# MSS_CTRL_MSS_CTRL_50D00000h register map
Vendor: Texas Instruments
Registers are 32-bit, read-write, reset values left out (the file's numbers can be read two ways) unless marked. A register's access mark holds for its fields unless they carry their own. Offsets are as the file gives them; [hi:lo] are bit positions; {n}, {i} and the like mark numbered series.

## MSS_CTRL (part 2 of 4)
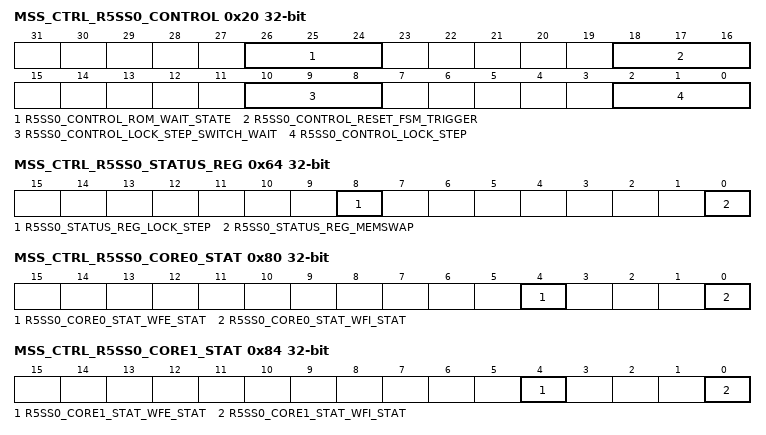
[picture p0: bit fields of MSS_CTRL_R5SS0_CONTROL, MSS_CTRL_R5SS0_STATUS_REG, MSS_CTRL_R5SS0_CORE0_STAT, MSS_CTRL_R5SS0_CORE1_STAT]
0x20 MSS_CTRL_R5SS0_CONTROL — This register is used to configure R5SS0 in Lock step or Dual core mode. The mode change can be affected only once in a SOC power cycle.
  [26:24] R5SS0_CONTROL_ROM_WAIT_STATE — Writing '111' enables a single cycle wait state with respect to CR5A_clk for rom access.This needs to be set when R5 clock is at 400MHZ and Interconnect-clk is at 200MHZ. [because it is a timing issue in this scenario]
  [18:16] R5SS0_CONTROL_RESET_FSM_TRIGGER — Write pulse bit field:Writing 3'b111 will trigger the reset FSM. Reset FSM ensures reset to R5SS and inturn ensures the latching of lock_step and also mem_swap bit
  [10:8] R5SS0_CONTROL_LOCK_STEP_SWITCH_WAIT — Writing 3'b111 ensures switch happens only after R5SS reset. Orelse it will be a immediate switch.
  [2:0] R5SS0_CONTROL_LOCK_STEP — Writing 3'b000 ensures R5 to be in Dual-Core mode. Note: The change happens after the R5SS reset assertion if corresponding R5SS_CONTROL_LOCK_STEP_SWITCH_WAIT is set. Or else the switiching to Dual-core happens on the fly.
0x28 MSS_CTRL_R5SS0_FORCE_WFI — This register is used to override and force WFI from R5SS0 to RCM.
  [2:0] R5SS0_FORCE_WFI_CR5_WFI_OVERIDE — Writing 3'b111 will force the wfi signals of R5SS to 1
0x40 MSS_CTRL_R5SS0_CORE0_HALT — This register is used to Halt or Unhalt R5SS0 Core 0
  [2:0] R5SS0_CORE0_HALT_HALT — Writing '000' will unhalt CR5A. This register should be written only once.
0x44 MSS_CTRL_R5SS0_CORE1_HALT — This register is used to Halt or Unhalt R5SS0 Core 1
  [2:0] R5SS0_CORE1_HALT_HALT — Writing '000' will unhalt for CR5B. This register should be written only once.
0x64 MSS_CTRL_R5SS0_STATUS_REG ro — This register shows whether R5SS0 is in Lock step or Dual core mode.
  [8] R5SS0_STATUS_REG_LOCK_STEP — Reading1:confirms R5SS is in lockstep mode. Reading0:confirms R5SS is in Dual-core mode.
  [0] R5SS0_STATUS_REG_MEMSWAP — Reading1:confirms ROM is Eclipsed from with RAM for R5.
0x80 MSS_CTRL_R5SS0_CORE0_STAT ro — This register shows the WFI WFE status of R5SS0 Core 0
  [4] R5SS0_CORE0_STAT_WFE_STAT — WFE Status
  [0] R5SS0_CORE0_STAT_WFI_STAT — WFI Status
0x84 MSS_CTRL_R5SS0_CORE1_STAT ro — This register shows the WFI WFE status of R5SS0 Core 1
  [4] R5SS0_CORE1_STAT_WFE_STAT — WFE Status
  [0] R5SS0_CORE1_STAT_WFI_STAT — WFI Status
0x150 MSS_CTRL_R5SS0_TEINIT — This register is used to set the Exception state of R5SS[x] at reset.
  [0] R5SS0_TEINIT_TEINIT — Exception handling state at reset. 0-ARM 1-Thumb
0x300 MSS_CTRL_R5SS0_ATCM_MEM_INIT — This register is used to initialise the data and ECC of ATCM memory of R5SS0 .
  [0] R5SS0_ATCM_MEM_INIT_MEM_INIT — Write_pulse bit field:Writing 1'b1 will start initializing the ATCM banks of CR5A/B. Value in each row is initialized to 0x0C_0000_0000
0x304 MSS_CTRL_R5SS0_ATCM_MEM_INIT_DONE access not given — This register is used to indicate the ATCM memory initialization completion for R5SS0.
  [0] R5SS0_ATCM_MEM_INIT_DONE_MEM_INIT_DONE — This field will be high once initialization of ATCM banks is finished. Writing 1'b1 would clear the bit. (access R/W1TC)
0x308 MSS_CTRL_R5SS0_ATCM_MEM_INIT_STATUS ro — This register is used to indicate the status of ongoing memory initialization for ATCM memory of R5SS0.
  [0] R5SS0_ATCM_MEM_INIT_STATUS_MEM_STATUS — 1'b0: No initialization is happening for ATCM banks of CR5A/B1'b1: Initialization is in progress for ATCM banks of CR5A/B
0x30C MSS_CTRL_R5SS0_BTCM_MEM_INIT — This register is used to initialise the data and ECC of BTCM memory of R5SS0 .
  [0] R5SS0_BTCM_MEM_INIT_MEM_INIT — Write_pulse bit field:Writing 1'b1 will start initializing the B0/1TCM banks of CR5A/B
0x310 MSS_CTRL_R5SS0_BTCM_MEM_INIT_DONE access not given — This register is used to indicate the BTCM memory initialization completion for R5SS0.
  [0] R5SS0_BTCM_MEM_INIT_DONE_MEM_INIT_DONE — This field will be high once initialization of B0/1TCM banks is finished. Writing 1'b1 would clear the bit. (access R/W1TC)
0x314 MSS_CTRL_R5SS0_BTCM_MEM_INIT_STATUS ro — This register is used to indicate the status of ongoing memory initialization for BTCM memory of R5SS0.
  [0] R5SS0_BTCM_MEM_INIT_STATUS_MEM_STATUS — 1'b0: No initialization is happening for B0/1TCM banks of CR5A/B1'b1: Initialization is in progress for B0/1TCM banks of CR5A/B
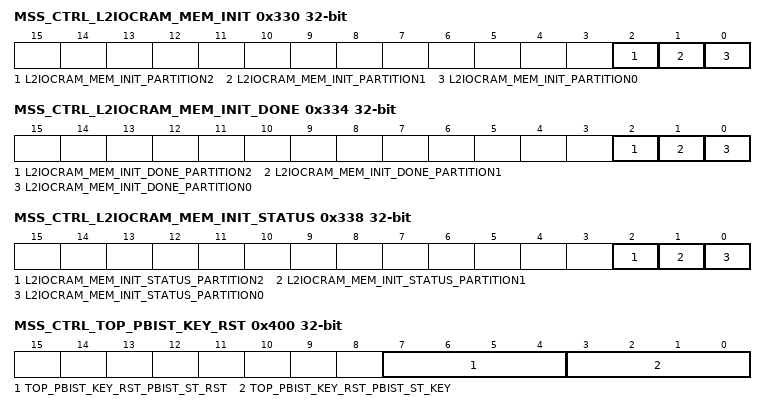
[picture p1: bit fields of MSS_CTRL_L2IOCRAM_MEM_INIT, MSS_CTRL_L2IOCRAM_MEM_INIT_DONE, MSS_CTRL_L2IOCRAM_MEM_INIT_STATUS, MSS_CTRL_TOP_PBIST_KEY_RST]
0x330 MSS_CTRL_L2IOCRAM_MEM_INIT — This register is used to initialise the data and ECC of L2OCRAM.
  [2] L2IOCRAM_MEM_INIT_PARTITION2 — Write_pulse bit field:Writing 1'b1 will start initializing the L2 Bank2. Value in each row is initialized to 0x0
  [1] L2IOCRAM_MEM_INIT_PARTITION1 — Write_pulse bit field:Writing 1'b1 will start initializing the L2 Bank1. Value in each row is initialized to 0x0
  [0] L2IOCRAM_MEM_INIT_PARTITION0 — Write_pulse bit field:Writing 1'b1 will start initializing the L2 Bank0. Value in each row is initialized to 0x0
0x334 MSS_CTRL_L2IOCRAM_MEM_INIT_DONE access not given — This register is used to indicate the L2OCRAM memory initialization completion .
  [2] L2IOCRAM_MEM_INIT_DONE_PARTITION2 — This field will be high once intialization of L2 bank2 is finished. Writing 1'b1 would clear the bit (access R/W1TC)
  [1] L2IOCRAM_MEM_INIT_DONE_PARTITION1 — This field will be high once intialization of L2 bank1 is finished. Writing 1'b1 would clear the bit (access R/W1TC)
  [0] L2IOCRAM_MEM_INIT_DONE_PARTITION0 — This field will be high once intialization of L2 bank0 is finished. Writing 1'b1 would clear the bit (access R/W1TC)
0x338 MSS_CTRL_L2IOCRAM_MEM_INIT_STATUS ro — This register is used to indicate the status of ongoing memory initialization for L2OCRAM.
  [2] L2IOCRAM_MEM_INIT_STATUS_PARTITION2 — 1'b0: No initialization is happening for L2 bank2 1'b1: Initialization is in progress for L2 bank2
  [1] L2IOCRAM_MEM_INIT_STATUS_PARTITION1 — 1'b0: No initialization is happening for L2 bank11'b1: Initialization is in progress for L2 bank1
  [0] L2IOCRAM_MEM_INIT_STATUS_PARTITION0 — 1'b0: No initialization is happening for L2 bank0 1'b1: Initialization is in progress for L2 bank0
0x33C MSS_CTRL_MAILBOXRAM_MEM_INIT — This register is used to initialise the data and ECC of MBOX_SRAM.
  [0] MAILBOXRAM_MEM_INIT_MEM0_INIT — Write_pulse bit field:Writing 1'b1 will start initializing the MSS_MBOX. Value in each row is initialized to 0x0
0x340 MSS_CTRL_MAILBOXRAM_MEM_INIT_DONE access not given — This register is used to indicate the MBOX_SRAM memory initialization completion .
  [0] MAILBOXRAM_MEM_INIT_DONE_MEM0_DONE — This field will be high once intialization of MSS_MBOX is finished. Writing 1'b1 would clear the bit (access R/W1TC)
0x344 MSS_CTRL_MAILBOXRAM_MEM_INIT_STATUS ro — This register is used to indicate the status of ongoing memory initialization for MBOX_SRAM.
  [0] MAILBOXRAM_MEM_INIT_STATUS_MEM0_STATUS — 1'b0: No initialization is happening for MSS_MBOX 1'b1: Initialization is in progress for MSS_MBOX
0x348 MSS_CTRL_TPCC_MEM_INIT — This register is used to initialise the data and ECC of EDMA_TPCC RAM.
  [0] TPCC_MEM_INIT_TPCC_A_MEMINIT_START — Write_pulse bit field:Writing 1'b1 will start initializing the MSS_TPCCA
0x34C MSS_CTRL_TPCC_MEM_INIT_DONE access not given — This register is used to indicate the EDMA_TPCC memory initialization completion .
  [0] TPCC_MEM_INIT_DONE_TPCC_A_MEMINIT_DONE — This field will be high once intialization of MSS_TPCCA is finished. Writing 1'b1 would clear the bit (access R/W1TC)
0x350 MSS_CTRL_TPCC_MEMINIT_STATUS ro — This register is used to indicate the status of ongoing memory initialization for EDMA_TPCC RAM.
  [0] TPCC_MEMINIT_STATUS_TPCC_A_MEMINIT_STATUS — 1'b0: No initialization is happening for MSS_TPCCA1'b1: Initialization is in progress for MSS_TPCCB
0x400 MSS_CTRL_TOP_PBIST_KEY_RST — This register is used to enable Top Pbist module.
  [7:4] TOP_PBIST_KEY_RST_PBIST_ST_RST — MSS PBIST controller will be brought out of reset when value is 0xA
  [3:0] TOP_PBIST_KEY_RST_PBIST_ST_KEY — Top PBIST Selftest Key. Valid value is 0x5
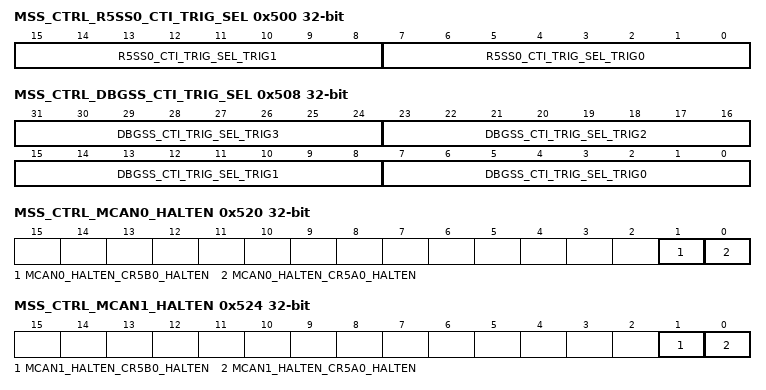
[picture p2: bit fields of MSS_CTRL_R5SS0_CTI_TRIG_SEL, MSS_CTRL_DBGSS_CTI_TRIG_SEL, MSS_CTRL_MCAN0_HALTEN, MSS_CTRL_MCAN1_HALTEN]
0x500 MSS_CTRL_R5SS0_CTI_TRIG_SEL — This register is used to select the two CTI trigger sources for R5SS[x]
  [15:8] R5SS0_CTI_TRIG_SEL_TRIG1 — Used for selecting the trigger source for 1st trigger of MSS_R5SS
  [7:0] R5SS0_CTI_TRIG_SEL_TRIG0 — Used for selecting the trigger source for 0th trigger of MSS_R5SS
0x508 MSS_CTRL_DBGSS_CTI_TRIG_SEL — This register is used to select thefour CTI trigger sources for DEBUGSS.
  [31:24] DBGSS_CTI_TRIG_SEL_TRIG3 — Used for selecting the trigger source for 3rd trigger of ONE_MCU_CTI
  [23:16] DBGSS_CTI_TRIG_SEL_TRIG2 — Used for selecting the trigger source for 2nd trigger of ONE_MCU_CTI
  [15:8] DBGSS_CTI_TRIG_SEL_TRIG1 — Used for selecting the trigger source for 1st trigger of ONE_MCU_CTI
  [7:0] DBGSS_CTI_TRIG_SEL_TRIG0 — Used for selecting the trigger source for 0th trigger of ONE_MCU_CTI
0x520 MSS_CTRL_MCAN0_HALTEN — This register selects which R5 CPU when debug halted shall halt MCAN[x] Peripheral.
  [1] MCAN0_HALTEN_CR5B0_HALTEN — 1'b0: IP Halt disabled with corresponding CPU halt1'b1: IP Halt enabled with corresponding CPU halt
  [0] MCAN0_HALTEN_CR5A0_HALTEN — 1'b0: IP Halt disabled with corresponding CPU halt1'b1: IP Halt enabled with corresponding CPU halt
0x524 MSS_CTRL_MCAN1_HALTEN — This register selects which R5 CPU when debug halted shall halt MCAN[x] Peripheral.
  [1] MCAN1_HALTEN_CR5B0_HALTEN — 1'b0: IP Halt disabled with corresponding CPU halt1'b1: IP Halt enabled with corresponding CPU halt
  [0] MCAN1_HALTEN_CR5A0_HALTEN — 1'b0: IP Halt disabled with corresponding CPU halt1'b1: IP Halt enabled with corresponding CPU halt
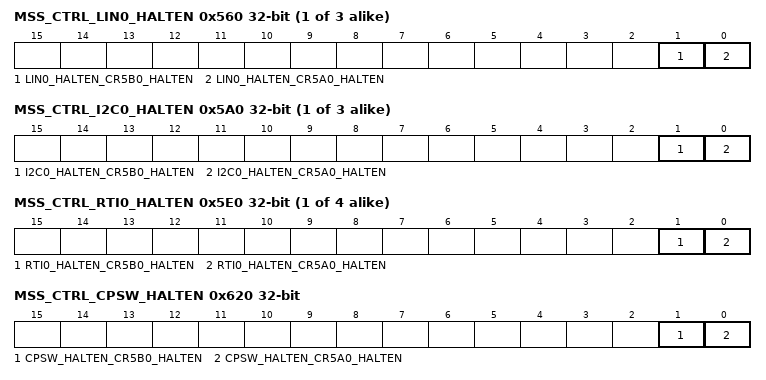
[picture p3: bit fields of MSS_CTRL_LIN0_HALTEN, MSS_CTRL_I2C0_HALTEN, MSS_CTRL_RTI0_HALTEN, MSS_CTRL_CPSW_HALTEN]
{0x560+4i} MSS_CTRL_LIN{i}_HALTEN (i=0..2) — This register selects which R5 CPU when debug halted shall halt LIN[x] Peripheral.
  [1] LIN{i}_HALTEN_CR5B0_HALTEN — 1'b0: IP Halt disabled with corresponding CPU halt1'b1: IP Halt enabled with corresponding CPU halt
  [0] LIN{i}_HALTEN_CR5A0_HALTEN — 1'b0: IP Halt disabled with corresponding CPU halt1'b1: IP Halt enabled with corresponding CPU halt
{0x5A0+4i} MSS_CTRL_I2C{i}_HALTEN (i=0..2) — This register selects which R5 CPU when debug halted shall halt I2C[x] Peripheral.
  [1] I2C{i}_HALTEN_CR5B0_HALTEN — 1'b0: IP Halt disabled with corresponding CPU halt1'b1: IP Halt enabled with corresponding CPU halt
  [0] I2C{i}_HALTEN_CR5A0_HALTEN — 1'b0: IP Halt disabled with corresponding CPU halt1'b1: IP Halt enabled with corresponding CPU halt
{0x5E0+4i} MSS_CTRL_RTI{i}_HALTEN (i=0..3) — This register selects which R5 CPU when debug halted shall halt RTI[x] Peripheral.
  [1] RTI{i}_HALTEN_CR5B0_HALTEN — 1'b0: IP Halt disabled with corresponding CPU halt1'b1: IP Halt enabled with corresponding CPU halt
  [0] RTI{i}_HALTEN_CR5A0_HALTEN — 1'b0: IP Halt disabled with corresponding CPU halt1'b1: IP Halt enabled with corresponding CPU halt
0x620 MSS_CTRL_CPSW_HALTEN — This register selects which R5 CPU when debug halted shall halt CPSW Peripheral.
  [1] CPSW_HALTEN_CR5B0_HALTEN — 1'b0: IP Halt disabled with corresponding CPU halt1'b1: IP Halt enabled with corresponding CPU halt
  [0] CPSW_HALTEN_CR5A0_HALTEN — 1'b0: IP Halt disabled with corresponding CPU halt1'b1: IP Halt enabled with corresponding CPU halt
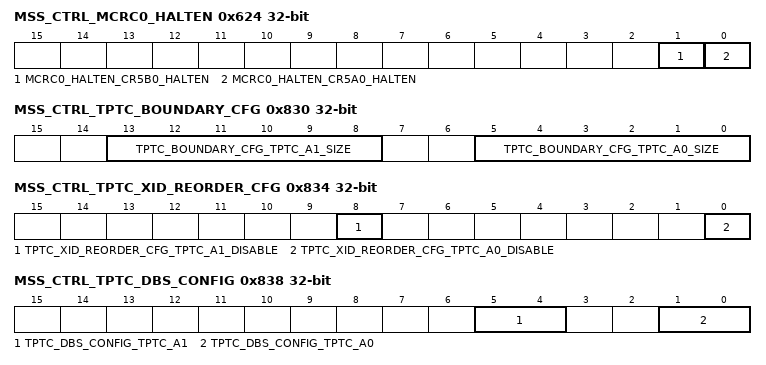
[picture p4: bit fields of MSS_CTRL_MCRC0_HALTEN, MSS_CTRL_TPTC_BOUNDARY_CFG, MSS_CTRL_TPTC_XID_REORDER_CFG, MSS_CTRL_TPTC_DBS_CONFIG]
0x624 MSS_CTRL_MCRC0_HALTEN — This register selects which R5 CPU when debug halted shall halt MCRC Peripheral.
  [1] MCRC0_HALTEN_CR5B0_HALTEN — 1'b0: IP Halt disabled with corresponding CPU halt1'b1: IP Halt enabled with corresponding CPU halt
  [0] MCRC0_HALTEN_CR5A0_HALTEN — 1'b0: IP Halt disabled with corresponding CPU halt1'b1: IP Halt enabled with corresponding CPU halt
0x830 MSS_CTRL_TPTC_BOUNDARY_CFG — TPTC_BOUNDARY_CFG.
  [13:8] TPTC_BOUNDARY_CFG_TPTC_A1_SIZE — 6 bit signal used for deciding the boundary crossing size for CID-RID-SID reordering of MSS_TPTC_A1Example: Writing 6'd19 decidies boundary to be 2^19 i.e. 512 KB
  [5:0] TPTC_BOUNDARY_CFG_TPTC_A0_SIZE — 6 bit signal used for deciding the boundary crossing size for CID-RID-SID reordering of MSS_TPTC_A0Example: Writing 6'd19 decidies boundary to be 2^19 i.e. 512 KB
0x834 MSS_CTRL_TPTC_XID_REORDER_CFG — TPTC_XID_REORDER_CFG.
  [8] TPTC_XID_REORDER_CFG_TPTC_A1_DISABLE — Writing 1'b1 will disable the CID-RID-SID reodering feature for MSS_TPTC_A1
  [0] TPTC_XID_REORDER_CFG_TPTC_A0_DISABLE — Writing 1'b1 will disable the CID-RID-SID reodering feature for MSS_TPTC_A0
0x838 MSS_CTRL_TPTC_DBS_CONFIG — This register controls the default burst size of EDMA TPTC.
  [5:4] TPTC_DBS_CONFIG_TPTC_A1 — DBS [default burst size] tieoff value for TPTC A1. DBS tieoff defines optimally sized cmd.Both the read and write controller will always issue commands that are less than or equal to the DBS tieoff value. This will typically be on the order of 4 or 8 dataphases worth of data. DBS must always be tied off to no larger than half of the Channel FIFO size. Set DBS to -2'b00 = 16 byte 2'b01 = 32 byte 2'b10 = 64 byte 2'b11 = 128 byte
  [1:0] TPTC_DBS_CONFIG_TPTC_A0 — DBS [default burst size] tieoff value for TPTC A0. DBS tieoff defines optimally sized cmd.Both the read and write controller will always issue commands that are less than or equal to the DBS tieoff value. This will typically be on the order of 4 or 8 dataphases worth of data. DBS must always be tied off to no larger than half of the Channel FIFO size. Set DBS to -2'b00 = 16 byte 2'b01 = 32 byte 2'b10 = 64 byte 2'b11 = 128 byte
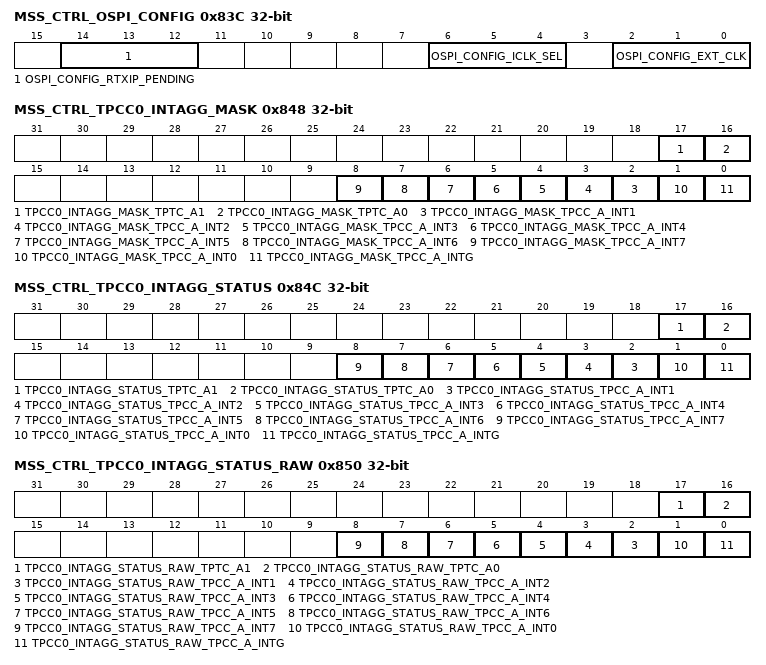
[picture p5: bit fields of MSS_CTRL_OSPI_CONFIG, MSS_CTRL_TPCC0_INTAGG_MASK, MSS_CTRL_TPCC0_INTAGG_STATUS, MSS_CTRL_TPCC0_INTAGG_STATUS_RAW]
0x83C MSS_CTRL_OSPI_CONFIG — OSPI_CONFIG.
  [14:12] OSPI_CONFIG_RTXIP_PENDING — Real time xip indication for OSPIWrite 3'b111 for real time xip is pendingWrite 3'b000 for real time xip is doneconfiguration changes must be done when FSS is idle/not configured/no transactions
  [6:4] OSPI_CONFIG_ICLK_SEL — Write 3'b111 to switch to loopback clock as OSPI input IO clockWrite 3'b000 to switch to OSPI DQS as OSPI input IO clockconfiguration changes must be done when FSS is idle/not configured/no transactions
  [2:0] OSPI_CONFIG_EXT_CLK — Write 3'b111 to external clock as OSPI baud clock source - needed for DFT IO char.
0x840 MSS_CTRL_OSPI_BOOT_CONFIG_MASK — OSPI_BOOT_CONFIG_MASK.
  [19:0] OSPI_BOOT_CONFIG_MASK_BOOT_SIZE — OSPI boot size registerconfiguration changes must be done when FSS is idle/not configured/no transactions
0x844 MSS_CTRL_OSPI_BOOT_CONFIG_SEG — OSPI_BOOT_CONFIG_SEG.
  [19:0] OSPI_BOOT_CONFIG_SEG_BOOT_SEG — OSPI segment selector for programmed boot sizeconfiguration changes must be done when FSS is idle/not configured/no transactions
0x848 MSS_CTRL_TPCC0_INTAGG_MASK — This register Masks selected interrupt soures from the Aggregated TPCC0 interrupt.
  [17] TPCC0_INTAGG_MASK_TPTC_A1 — Mask Interrupt from TPTC A1 to aggregated Interrupt MSS_TPCC_A_INTAGG1'b1 Interrupt is Masked1'b0 Interrupt is Unmasked
  [16] TPCC0_INTAGG_MASK_TPTC_A0 — Mask Interrupt from TPTC A0 to aggregated Interrupt MSS_TPCC_A_INTAGG1'b1 Interrupt is Masked1'b0 Interrupt is Unmasked
  [n+1] TPCC0_INTAGG_MASK_TPCC_A_INT{n} (n=1..7) — Mask Interrupt from MSS_TPCC_A to aggregated Interrupt MSS_TPCC_A_INTAGG1'b1 Interrupt is Masked1'b0 Interrupt is Unmasked
  [1] TPCC0_INTAGG_MASK_TPCC_A_INT0 — Mask Interrupt from TPCC A to aggregated Interrupt MSS_TPCC_A_INTAGG1'b1 Interrupt is Masked1'b0 Interrupt is Unmasked
  [0] TPCC0_INTAGG_MASK_TPCC_A_INTG — Mask Interrupt from MSS_TPCC_A to aggregated Interrupt MSS_TPCC_A_INTAGG1'b1 Interrupt is Masked1'b0 Interrupt is Unmasked
0x84C MSS_CTRL_TPCC0_INTAGG_STATUS access not given — This register shows the Status of Unmasked Interrupts from TPCC0.
  [17] TPCC0_INTAGG_STATUS_TPTC_A1 — Status of Interrupt from TPTC A1. Set only if Interupt is unmasked in TPCC0_INTAGG_MASKWrie 0x1 to clear this interrupt. (access R/W1TC)
  [16] TPCC0_INTAGG_STATUS_TPTC_A0 — Status of Interrupt from TPTC A0. Set only if Interupt is unmasked in TPCC0_INTAGG_MASKWrie 0x1 to clear this interrupt. (access R/W1TC)
  [n+1] TPCC0_INTAGG_STATUS_TPCC_A_INT{n} (n=1..7) — Status of Interrupt from MSS_TPCC_A. Set only if Interupt is unmasked in TPCC0_INTAGG_MASKWrie 0x1 to clear this interrupt. (access R/W1TC)
  [1] TPCC0_INTAGG_STATUS_TPCC_A_INT0 — Status of Interrupt from TPCC A Set only if Interupt is unmasked in TPCC0_INTAGG_MASKWrie 0x1 to clear this interrupt. (access R/W1TC)
  [0] TPCC0_INTAGG_STATUS_TPCC_A_INTG — Status of Interrupt from MSS_TPCC_A. Set only if Interupt is unmasked in TPCC0_INTAGG_MASKWrie 0x1 to clear this interrupt. (access R/W1TC)
0x850 MSS_CTRL_TPCC0_INTAGG_STATUS_RAW access not given — This register shows the Status of all Interrupts from TPCC0.
  [17] TPCC0_INTAGG_STATUS_RAW_TPTC_A1 — Raw Status of Interrupt from TPTC A1. Set irrespective if the Interupt is masked or unmasked in TPCC0_INTAGG_MASK (access R/W1TC)
  [16] TPCC0_INTAGG_STATUS_RAW_TPTC_A0 — Raw Status of Interrupt from TPTC A0. Set irrespective if the Interupt is masked or unmasked in TPCC0_INTAGG_MASK (access R/W1TC)
  [n+1] TPCC0_INTAGG_STATUS_RAW_TPCC_A_INT{n} (n=1..7) — Raw Status of Interrupt from MSS_TPCC_A. Set irrespective if the Interupt is masked or unmasked in MSS_TPCC_C_INTAGG_MASK (access R/W1TC)
  [1] TPCC0_INTAGG_STATUS_RAW_TPCC_A_INT0 — Raw Status of Interrupt from TPCC A. Set irrespective if the Interupt is masked or unmasked in TPCC0_INTAGG_MASK (access R/W1TC)
  [0] TPCC0_INTAGG_STATUS_RAW_TPCC_A_INTG — Raw Status of Interrupt from MSS_TPCC_A. Set irrespective if the Interupt is masked or unmasked in MSS_TPCC_C_INTAGG_MASK (access R/W1TC)
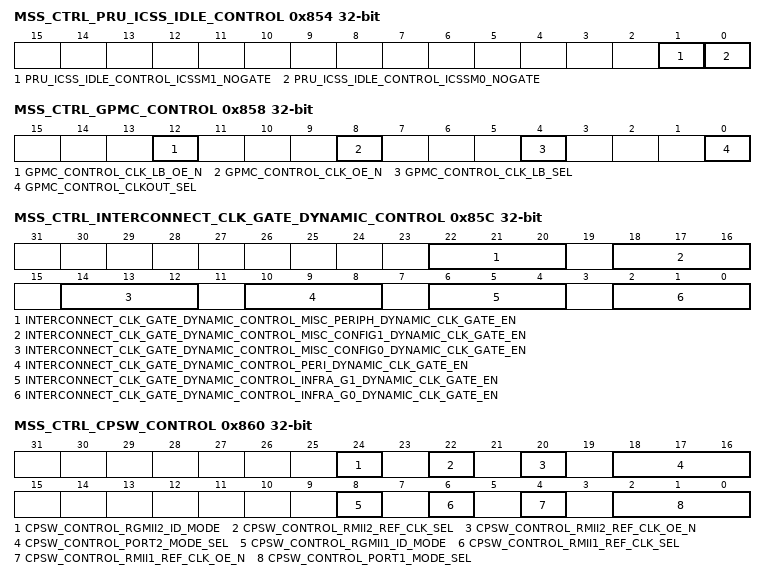
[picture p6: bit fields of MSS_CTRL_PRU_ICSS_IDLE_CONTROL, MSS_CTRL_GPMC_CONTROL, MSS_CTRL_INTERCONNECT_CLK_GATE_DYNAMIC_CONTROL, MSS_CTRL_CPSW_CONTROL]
0x854 MSS_CTRL_PRU_ICSS_IDLE_CONTROL — This register cofigures the Idle mode behaviour of ICSSM.
  [1] PRU_ICSS_IDLE_CONTROL_ICSSM1_NOGATE — Writing 1'b0 will enable local auto-clock gating [lower power] at IP level with increase in access/functional latency. Following IPs are controlled with this signalICSSM1
  [0] PRU_ICSS_IDLE_CONTROL_ICSSM0_NOGATE — Writing 1'b0 will enable local auto-clock gating [lower power] at IP level with increase in access/functional latency. Following IPs are controlled with this signalICSSM0
0x858 MSS_CTRL_GPMC_CONTROL — This register is used to configure the GPMC Clock source and Loop Back clock Source.
  [12] GPMC_CONTROL_CLK_LB_OE_N — GPMC_CLK_LB oe_n1:GPMC_dev_clk is driven to pad0:GPMC_dev_clk is not driven to pad
  [8] GPMC_CONTROL_CLK_OE_N — GPMC_CLKOUT oe_n1:GPMC_dev_clk mux output is driven to pad0:GPMC_dev_clk mux output is not driven to pad
  [4] GPMC_CONTROL_CLK_LB_SEL — GPMC_CLK_LB sel0:GPMC_CLK_LB pad clock1:GPMC_CLK pad clock
  [0] GPMC_CONTROL_CLKOUT_SEL — GPMC_CLKOUT sel0:GPMC_func_clock1:GPMC_dev clock
0x85C MSS_CTRL_INTERCONNECT_CLK_GATE_DYNAMIC_CONTROL — This register has dynamic clock gating enable for interconnects.
  [22:20] INTERCONNECT_CLK_GATE_DYNAMIC_CONTROL_MISC_PERIPH_DYNAMIC_CLK_GATE_EN — dynamic clock gate feature enable. Multibit writeWrite 0x111 to enable Write 0x000 to disable2 extra clock latency for the first access after the clock is gated and SCRP_PERI is not gated
  [18:16] INTERCONNECT_CLK_GATE_DYNAMIC_CONTROL_MISC_CONFIG1_DYNAMIC_CLK_GATE_EN — dynamic clock gate feature enable. Multibit writeWrite 0x111 to enable Write 0x000 to disable2 extra clock latency for the first access after the clock is gated and SCRP_PERI is not gated
  [14:12] INTERCONNECT_CLK_GATE_DYNAMIC_CONTROL_MISC_CONFIG0_DYNAMIC_CLK_GATE_EN — dynamic clock gate feature enable. Multibit writeWrite 0x111 to enable Write 0x000 to disable2 extra clock latency for the first access after the clock is gated and SCRP_PERI is not gated
  [10:8] INTERCONNECT_CLK_GATE_DYNAMIC_CONTROL_PERI_DYNAMIC_CLK_GATE_EN — dynamic clock gate feature enable. Multibit writeWrite 0x111 to enable Write 0x000 to disable2 extra clock latency for the first access after the clock is gated and SCRP_PERI is not gated
  [6:4] INTERCONNECT_CLK_GATE_DYNAMIC_CONTROL_INFRA_G1_DYNAMIC_CLK_GATE_EN — dynamic clock gate feature enable. Multibit writeWrite 0x111 to enable Write 0x000 to disable2 extra clock latency for the first access after the clock is gated and SCRP_PERI is not gated4 extra clock latency for the first access after the clock is gated and SCRP_PERI is gated
  [2:0] INTERCONNECT_CLK_GATE_DYNAMIC_CONTROL_INFRA_G0_DYNAMIC_CLK_GATE_EN — dynamic clock gate feature enable. Multibit writeWrite 0x111 to enable Write 0x000 to disable2 extra clock latency for the first access after the clock is gated and SCRP_PERI is not gated4 extra clock latency for the first access after the clock is gated and SCRP_PERI is gated
0x860 MSS_CTRL_CPSW_CONTROL — This register is used to control the CPSW Ethernet modes and additional controls on the IO.
  [24] CPSW_CONTROL_RGMII2_ID_MODE — Internal delay mode for port 2. Only for TX0 : ID mode is disabled1 : ID mode is enabled
  [22] CPSW_CONTROL_RMII2_REF_CLK_SEL — To select the rmii_ref_clk loopback mux output either from PAD or from MSS_RCM. Write 0 to get clock will be from IO pad[pad loopback]. Write 1 to get clock from internal loopback.
  [20] CPSW_CONTROL_RMII2_REF_CLK_OE_N — RMII_REF_CLK IO Output enable control1'b0 Output enable1'b1 Output Disable
  [18:16] CPSW_CONTROL_PORT2_MODE_SEL — Port 2 Interface 3'b000 = MII3'b001 = RMII3'b010 = RGMII3'b011 - 111 = Not Supported
  [8] CPSW_CONTROL_RGMII1_ID_MODE — Internal delay mode for port 1. Only for TX0 : ID mode is disabled1 : ID mode is enabled
  [6] CPSW_CONTROL_RMII1_REF_CLK_SEL — To select the rmii_ref_clk loopback mux output either from PAD or from MSS_RCM. Write 1'b0 to get clock will be from IO pad[pad loopback]. Write 1'b1 to get clock from internal source
  [4] CPSW_CONTROL_RMII1_REF_CLK_OE_N — RMII_REF_CLK IO Output enable control1'b0 Output enable1'b1 Output Disable
  [2:0] CPSW_CONTROL_PORT1_MODE_SEL — Port 1 Interface 3'b000 = MII3'001 = RMII3'010 = RGMII3'b011 - 111 = Not Supported
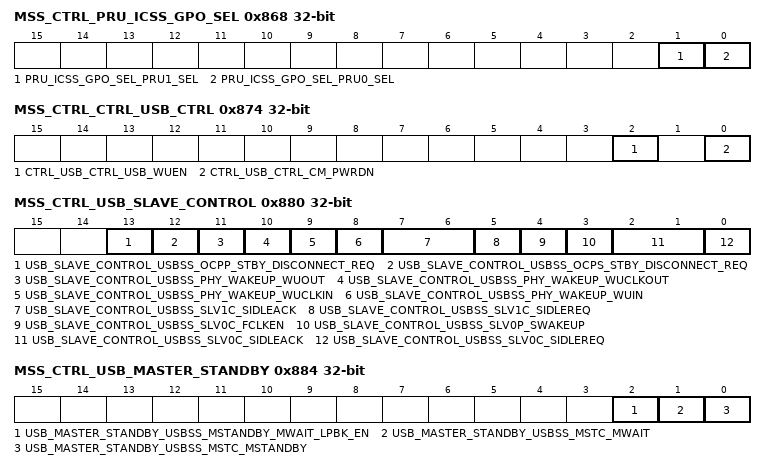
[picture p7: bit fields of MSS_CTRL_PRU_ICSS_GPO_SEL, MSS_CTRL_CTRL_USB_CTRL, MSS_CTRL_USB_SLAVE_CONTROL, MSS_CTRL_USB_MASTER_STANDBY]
0x868 MSS_CTRL_PRU_ICSS_GPO_SEL — This Register is used to select between icssm0 gpo and icssm1 gpo.
  [1] PRU_ICSS_GPO_SEL_PRU1_SEL — Mux select field which Selects between icssm0_pru1_gpo & icssm1_pru1_gpo:1'h0 :icssm0_pru1_gpo1'h1:icssm1_pru1_gpoThe output of the mux is going as input to inputXBAR,mdlXBAR,iclXBAR.Refer to C2K XBAR section for details
  [0] PRU_ICSS_GPO_SEL_PRU0_SEL — Mux select field which Selects between icssm0_pru0_gpo & icssm1_pru0_gpo:1'h0 :icssm0_pru0_gpo1'h1:icssm1_pru0_gpoThe output of the mux is going as input to inputXBAR,mdlXBAR,iclXBAR.Refer to C2K XBAR section for details
0x874 MSS_CTRL_CTRL_USB_CTRL — This register is used to control the usb registers.
  [2] CTRL_USB_CTRL_USB_WUEN — USB Wakeup Enable
  [0] CTRL_USB_CTRL_CM_PWRDN — Power down the USB CM PHY1 : PHY Powered down0 : PHY in normal mode
0x878 MSS_CTRL_CTRL_USB_STS ro — This register is used to check the status of Charger Detection.
  [0] CTRL_USB_STS_WUEVT — Wakeup Event
0x880 MSS_CTRL_USB_SLAVE_CONTROL access per field — This register is used to control the USB Slave Requests and check the Acknowledgement.
  [13] USB_SLAVE_CONTROL_USBSS_OCPP_STBY_DISCONNECT_REQ rw — USB OCPP standby disconnect request
  [12] USB_SLAVE_CONTROL_USBSS_OCPS_STBY_DISCONNECT_REQ rw — USB OCPS standby disconnect request
  [11] USB_SLAVE_CONTROL_USBSS_PHY_WAKEUP_WUOUT ro — wakeup out
  [10] USB_SLAVE_CONTROL_USBSS_PHY_WAKEUP_WUCLKOUT ro — wakeup clock out
  [9] USB_SLAVE_CONTROL_USBSS_PHY_WAKEUP_WUCLKIN rw — wakeup clock in
  [8] USB_SLAVE_CONTROL_USBSS_PHY_WAKEUP_WUIN rw — wakeup in
  [7:6] USB_SLAVE_CONTROL_USBSS_SLV1C_SIDLEACK ro — Idle11:SF is in a quiet state funt00:SF is fully functional sleeptrans01:sleep transition ongoing
  [5] USB_SLAVE_CONTROL_USBSS_SLV1C_SIDLEREQ rw — 1: PRCM requests SF to go in a quiet state 0:PRCM requests SF to be functional
  [4] USB_SLAVE_CONTROL_USBSS_SLV0C_FCLKEN rw — Qualifies below idle request 1:applies only to interface clock 0:applies to both interface and functional clock
  [3] USB_SLAVE_CONTROL_USBSS_SLV0P_SWAKEUP ro — 1: SF requests PRCM to restore power/clock and put it back into functional state 0:SF does not request wakeup
  [2:1] USB_SLAVE_CONTROL_USBSS_SLV0C_SIDLEACK ro — Idle11:SF is in a quiet statefunt00:SF is fully functionalsleeptrans01:sleep transition ongoing
  [0] USB_SLAVE_CONTROL_USBSS_SLV0C_SIDLEREQ rw — 1: PRCM requests SF[] to go in a quiet state 0:PRCM requests SF to be functional
0x884 MSS_CTRL_USB_MASTER_STANDBY access per field — This register is used to set the control the pwrStandby interface.
  [2] USB_MASTER_STANDBY_USBSS_MSTANDBY_MWAIT_LPBK_EN rw — 1: Mstandby to mwait loopback enabled where mwait is fed by mstanby signal,0:Mwait is gived by usbss_mstc_Mwait MMR bit0:PRCM allows SAF to be fully functional
  [1] USB_MASTER_STANDBY_USBSS_MSTC_MWAIT rw — 1: PRCM acknowledge the quiescent state of the SAF 0:PRCM allows SAF to be fully functional
  [0] USB_MASTER_STANDBY_USBSS_MSTC_MSTANDBY ro — 1: SAF is in a quiet state 0:SAF is functional or need to become functional
0x88C MSS_CTRL_USB_UTMI_DRVVBUS_CONTROL — This register sets the UTMI_DRVVBUS bits of USB.
  [0] USB_UTMI_DRVVBUS_CONTROL_USBSS_DRVVBUS_CONTROL — 0: phy_utmi_drvvbus=utmi_drvvbus from USB_core, Scenario: Normal USB operation. phy_utmi_drvvbus is sourced from the USB core.1:phy_utmi_drvvbus=1, Scenario: Host non-otg.
0x890 MSS_CTRL_USB_SPAREOUT — This register checks the spareout bits of USB.
  [0] USB_SPAREOUT_AUTORESUME_EN — This bit controls USB autoresume functionality. When set to 1 it detects resume signaling on DP/DM when in Suspend mode and perform autoresume sequence
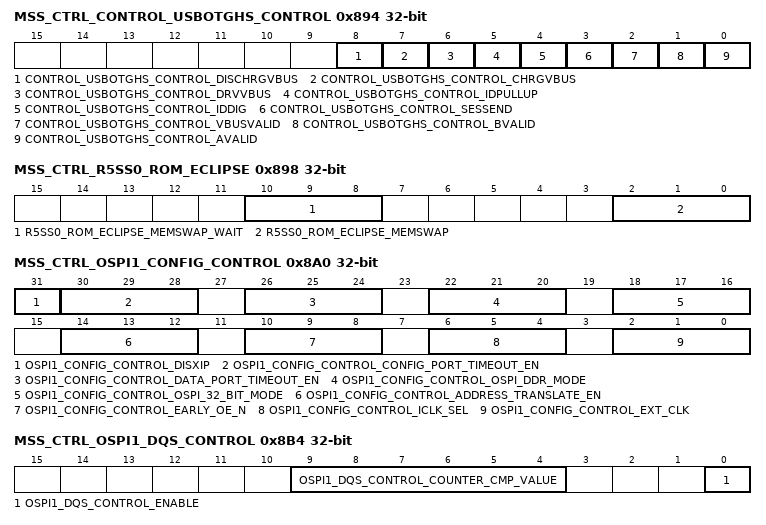
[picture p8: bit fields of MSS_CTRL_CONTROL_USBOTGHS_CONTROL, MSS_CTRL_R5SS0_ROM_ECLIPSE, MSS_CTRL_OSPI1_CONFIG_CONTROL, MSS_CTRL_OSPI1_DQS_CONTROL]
0x894 MSS_CTRL_CONTROL_USBOTGHS_CONTROL access per field — This register configures the .
  [8] CONTROL_USBOTGHS_CONTROL_DISCHRGVBUS ro — USBOTGHS value for signal dischrgvbus [OTG_PD_VBUS ]. controls discharging of VBUS forcompleting SRP.Read 0x0: OTG transceiver does not discharge VBUSRead 0x1: OTG transceiver discharges VBUS
  [7] CONTROL_USBOTGHS_CONTROL_CHRGVBUS ro — USBOTGHS value for signal chrgvbus [OTG_PU_VBUS]. controls charging of VBUS for initiating SRP.Read 0x0: OTG transceiver does not charge VBUSRead 0x1: OTG transceiver charges VBUS
  [6] CONTROL_USBOTGHS_CONTROL_DRVVBUS ro — USBOTGHS value for signal drvvbus[OTG_DRV_VBUS]. controls the driving of 5V power onVBUS.Read 0x0: OTG transceiver does not drive VBUSRead 0x1: OTG transceiver drives VBUS
  [5] CONTROL_USBOTGHS_CONTROL_IDPULLUP ro — USBOTGHS value for signal Idpullup [OTG_PU_ID].Enables sampling of the ID pin of the USB connector.Read 0x0: OTG transceiver does not apply a pullup to IDRead 0x1: OTG transceiver applies a pullup to ID
  [4] CONTROL_USBOTGHS_CONTROL_IDDIG rw — Sets the USBOTGHS signal iddig [ID]. Indicates the value of the ID pin of the USB connector.0x0: ID pin is grounded0x1: ID pin is high-impedance
  [3] CONTROL_USBOTGHS_CONTROL_SESSEND rw — Sets the USBOTGHS signal sessend [BSESSEND].Indicates if VBUS is below the B-Device session endthreshold. The threshold Vth is between 0.2V and 0.8V.0x0: VBUS voltage is above VB_SESS_END.0x1: VBUS voltage is below VB_SESS_END.
  [2] CONTROL_USBOTGHS_CONTROL_VBUSVALID rw — Sets the USBOTGHS signal vbusvalid [VBUSVLD].Indicates if VBUS is above the threshold for normaloperation. The threshold Vth is between 4.4V and 4.75V.
  [1] CONTROL_USBOTGHS_CONTROL_BVALID rw — Sets the USBOTGHS signal bvalid [BSESSVLD]. Signalis currently unconnected [reserved for future use].0x0: VBUS voltage is below VB_SESS_VLD0x1: VBUS voltage is above VB_SESS_VLD
  [0] CONTROL_USBOTGHS_CONTROL_AVALID rw — Sets the USBOTGHS signal avalid [ASESSVLD].Indicates if VBUS is above the A-Device session validthreshold. The threshold Vth is between 0.8V and 2.0V.0x0: VBUS voltage is below VA_SESS_VLD0x1: VBUS voltage is above VA_SESS_VLD
0x898 MSS_CTRL_R5SS0_ROM_ECLIPSE — R5_ROM_ECLIPSE.
  [10:8] R5SS0_ROM_ECLIPSE_MEMSWAP_WAIT — Writing 3'b111 ensures ROM-Eclipsing happens only after R5SS reset. Orelse it will be a immediate change.
  [2:0] R5SS0_ROM_ECLIPSE_MEMSWAP — Writing '111' ensures eclipsing of CR5A_ROM immediately if memswap_wait is not set. If memswap_wait is set then ROM is eclipsed after R5SS reset assertion.
0x8A0 MSS_CTRL_OSPI1_CONFIG_CONTROL — This register is used for OSPI1 IP configurations .
  [31] OSPI1_CONFIG_CONTROL_DISXIP — This field is used to disable XIPprefetching. 0 XIP Prefetch Enabled. 1 XIP prefetch disabled Please note that this is referring to prefetching feature that is useful for linear accesses associated with XIP. This is NOT referring to XIP features implemented in flash Controller or memory device.
  [30:28] OSPI1_CONFIG_CONTROL_CONFIG_PORT_TIMEOUT_EN — Multibit writeWrite 3'b111 to enable config port timeout logicWrite 3'b000 to disable config port timeout logic
  [26:24] OSPI1_CONFIG_CONTROL_DATA_PORT_TIMEOUT_EN — Multibit writeWrite 3'b111 to enable data port timeout logicWrite 3'b000 to dis+S3669able data port timeout logic
  [22:20] OSPI1_CONFIG_CONTROL_OSPI_DDR_MODE — Multibit writeWrite 3'b111 to enable ddr modeWrite 3'b000 to disable ddr mode
  [18:16] OSPI1_CONFIG_CONTROL_OSPI_32_BIT_MODE — Multibit writeWrite 3'b111 to enable 32 bit modeWrite 3'b000 to disable 32 bit mode
  [14:12] OSPI1_CONFIG_CONTROL_ADDRESS_TRANSLATE_EN — Multibit writeWrite 3'b111 to enable the address translation for iSSI PSRAM memoryWrite 3'b000 to disable the address translation for non iSSI PSRAM memory
  [10:8] OSPI1_CONFIG_CONTROL_EARLY_OE_N — Multibit writeThe signal controls the early enable for OE for OSPI1 data.Write 3'b111 to enableWrite 3'b000 to disable
  [6:4] OSPI1_CONFIG_CONTROL_ICLK_SEL — Multibit writeWrite 3'b111 to switch to loopback clock as OSPI input IO clockWrite 3'b000 to switch to OSPI DQS as OSPI input IO clockconfiguration changes must be done when FSS is idle/not configured/no transactions
  [2:0] OSPI1_CONFIG_CONTROL_EXT_CLK — Multibit writeWrite 3'b111 to external clock as OSPI baud clock source - needed for DFT IO char.Write 3'b000 to OSPI1 clock as OSPI baud clock source - needed for DFT IO
0x8B4 MSS_CTRL_OSPI1_DQS_CONTROL — This register is used for DQS control of OSPI1 IP .
  [9:4] OSPI1_DQS_CONTROL_COUNTER_CMP_VALUE — write the overall count required for waiting before driving dqs oe_n . Configure the [dummy cycle+ address phase+command phase clocks]/2
  [0] OSPI1_DQS_CONTROL_ENABLE — write 1'b1 to enable the dqs HW based counter. Write 1'b0 to disable the dqs HW based counter
0x8B8 MSS_CTRL_USB_OCPS_STBY_DISCONNECT_ACK access not given — Register provides the status for OCPS disconnect request from mater.
  [0] USB_OCPS_STBY_DISCONNECT_ACK_USBSS_OCPS_STBY_DISCONNECT_ACK — USB OCPS standby disconnect acknowledgement (access R/W1TC)
0x8BC MSS_CTRL_USB_OCPP_STBY_DISCONNECT_ACK access not given — Register provides the status for OCPP disconnect request from mater.
  [0] USB_OCPP_STBY_DISCONNECT_ACK_USBSS_OCPP_STBY_DISCONNECT_ACK — USB OCPP standby disconnect acknowledgement (access R/W1TC)
0x1008 MSS_CTRL_LOCK0_KICK0 — - KICK0 component.
  [31:0] LOCK0_KICK0 — - KICK0 component
0x100C MSS_CTRL_LOCK0_KICK1 — - KICK1 component.
  [31:0] LOCK0_KICK1 — - KICK1 component
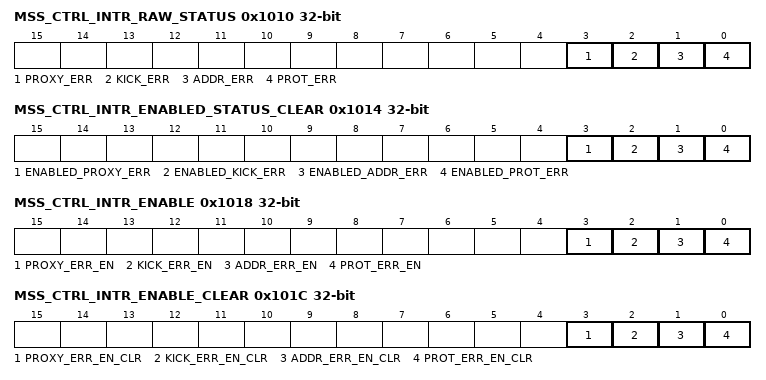
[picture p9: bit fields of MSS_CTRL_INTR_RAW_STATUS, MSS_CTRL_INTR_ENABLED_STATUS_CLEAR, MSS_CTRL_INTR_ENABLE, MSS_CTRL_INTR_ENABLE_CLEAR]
0x1010 MSS_CTRL_INTR_RAW_STATUS access not given — Interrupt Raw Status/Set Register.
  [3] PROXY_ERR — Proxy0 access violation error. Raw status is read. Write a 1 to set the status. Writing a 0 has no effect. (access R/W1TS)
  [2] KICK_ERR — Kick access violation error. Raw status is read. Write a 1 to set the status. Writing a 0 has no effect. (access R/W1TS)
  [1] ADDR_ERR — Addressing violation error. Raw status is read. Write a 1 to set the status. Writing a 0 has no effect. (access R/W1TS)
  [0] PROT_ERR — Protection violation error. Raw status is read. Write a 1 to set the status. Writing a 0 has no effect. (access R/W1TS)
0x1014 MSS_CTRL_INTR_ENABLED_STATUS_CLEAR access not given — Interrupt Enabled Status/Clear register.
  [3] ENABLED_PROXY_ERR — Proxy0 access violation error. Enabled status is read. Write a 1 to clear the status. Writing a 0 has no effect. (access R/W1TC)
  [2] ENABLED_KICK_ERR — Kick access violation error. Enabled status is read. Write a 1 to clear the status. Writing a 0 has no effect. (access R/W1TC)
  [1] ENABLED_ADDR_ERR — Addressing violation error. Enabled status is read. Write a 1 to clear the status. Writing a 0 has no effect. (access R/W1TC)
  [0] ENABLED_PROT_ERR — Protection violation error. Enabled status is read. Write a 1 to clear the status. Writing a 0 has no effect. (access R/W1TC)
0x1018 MSS_CTRL_INTR_ENABLE access not given — Interrupt Enable register.
  [3] PROXY_ERR_EN — Proxy0 access violation error enable. Write a 1 to set the enable. Writing a 0 has no effect. (access R/W1TS)
  [2] KICK_ERR_EN — Kick access violation error enable. Write a 1 to set the enable. Writing a 0 has no effect. (access R/W1TS)
  [1] ADDR_ERR_EN — Addressing violation error enable. Write a 1 to set the enable. Writing a 0 has no effect. (access R/W1TS)
  [0] PROT_ERR_EN — Protection violation error enable. Write a 1 to set the enable. Writing a 0 has no effect. (access R/W1TS)
0x101C MSS_CTRL_INTR_ENABLE_CLEAR access not given — Interrupt Enable Clear register.
  [3] PROXY_ERR_EN_CLR — Proxy0 access violation error enable clear. Write a 1 to clear the enable. Writing a 0 has no effect. (access R/W1TC)
  [2] KICK_ERR_EN_CLR — Kick access violation error enable clear. Write a 1 to clear the enable. Writing a 0 has no effect. (access R/W1TC)
  [1] ADDR_ERR_EN_CLR — Addressing violation error enable clear. Write a 1 to clear the enable. Writing a 0 has no effect. (access R/W1TC)
  [0] PROT_ERR_EN_CLR — Protection violation error enable clear. Write a 1 to clear the enable. Writing a 0 has no effect. (access R/W1TC)
0x1020 MSS_CTRL_EOI — EOI register.
  [7:0] EOI_VECTOR — EOI vector value. Write this with interrupt distribution value in the chip.
0x1024 MSS_CTRL_FAULT_ADDRESS ro — Fault Address register.
  [31:0] FAULT_ADDR — Fault Address.
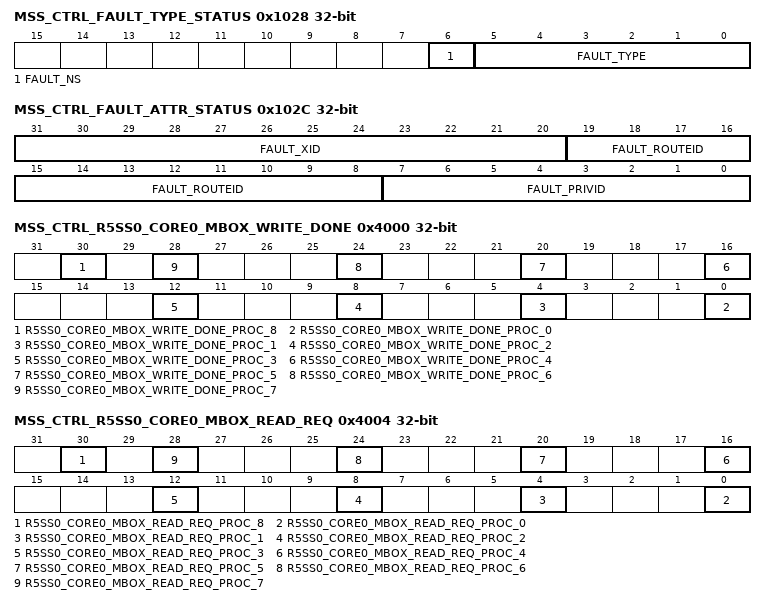
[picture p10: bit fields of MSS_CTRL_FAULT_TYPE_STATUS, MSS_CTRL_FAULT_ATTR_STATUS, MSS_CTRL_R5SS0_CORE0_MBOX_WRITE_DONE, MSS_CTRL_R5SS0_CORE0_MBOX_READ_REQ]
0x1028 MSS_CTRL_FAULT_TYPE_STATUS ro — Fault Type Status register.
  [6] FAULT_NS — Non-secure access.
  [5:0] FAULT_TYPE — Fault Type 10_0000 = Supervisor read fault - priv = 1 dir = 1 dtype != 1 01_0000 = Supervisor write fault - priv = 1 dir = 0 00_1000 = Supervisor execute fault - priv = 1 dir = 1 dtype = 1 00_0100 = User read fault - priv = 0 dir = 1 dtype = 1 00_0010 = User write fault - priv = 0 dir = 0 00_0001 = User execute fault - priv = 0 dir = 1 dtype = 1 00_0000 = No fault
0x102C MSS_CTRL_FAULT_ATTR_STATUS ro — Fault Attribute Status register.
  [31:20] FAULT_XID — XID.
  [19:8] FAULT_ROUTEID — Route ID.
  [7:0] FAULT_PRIVID — Privilege ID.
0x1030 MSS_CTRL_FAULT_CLEAR wo — Fault Clear register.
  [0] FAULT_CLR — Fault clear. Writing a 1 clears the current fault. Writing a 0 has no effect.
0x4000 MSS_CTRL_R5SS0_CORE0_MBOX_WRITE_DONE — This register is used by R5SS0 Core 0 to generate Mailbox interrupt to Recipent CPU.
  [30] R5SS0_CORE0_MBOX_WRITE_DONE_PROC_8 — Write pulse bit field:This register should be written once finishing Writing into the mailbox memory of processor 8
  [4n] R5SS0_CORE0_MBOX_WRITE_DONE_PROC_{n} (n=0..7) — Write pulse bit field:This register should be written once finishing Writing into the mailbox memory of processor {n}
0x4004 MSS_CTRL_R5SS0_CORE0_MBOX_READ_REQ access not given — This register is used by R5SS0 Core 0 to know the Sender of Mailbox Interrupt as well as clear it.
  [30] R5SS0_CORE0_MBOX_READ_REQ_PROC_8 — This is request from processor 8 to mss_cr5a. Requesting it to read from mailbox. (access R/W1TC)
  [4n] R5SS0_CORE0_MBOX_READ_REQ_PROC_{n} (n=0..7) — This is request from processor {n} to mss_cr5a. Requesting it to read from mailbox. (access R/W1TC)
0x4008 MSS_CTRL_R5SS0_CORE0_MBOX_READ_DONE_ACK — This register is used by R5SS0 Core 0 to generate Mailbox Read acknowledgement to the Sender CPU.
  [8:0] R5SS0_CORE0_MBOX_READ_DONE_ACK_PROC — Write pulse bit field:For bits 0 to7:Wrting1'b1 : Generates pulse interrupt to corresponding proc from MSS_CR5
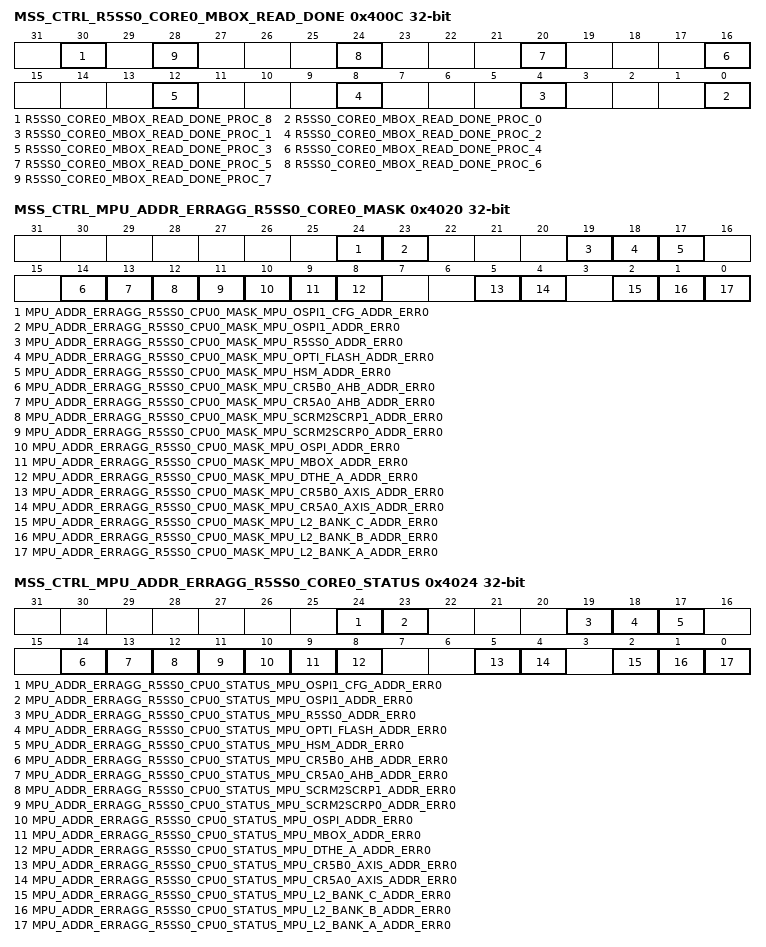
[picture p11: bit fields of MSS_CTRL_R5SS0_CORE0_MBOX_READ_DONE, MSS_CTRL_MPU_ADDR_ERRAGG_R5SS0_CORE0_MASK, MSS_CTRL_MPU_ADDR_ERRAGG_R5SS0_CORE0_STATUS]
0x400C MSS_CTRL_R5SS0_CORE0_MBOX_READ_DONE access not given — This register is used by R5SS0 Core 0 to know that the Receiver CPU has read the Mailbox and Acked. It is also used to clear the Read Done Interrupt.
  [30] R5SS0_CORE0_MBOX_READ_DONE_PROC_8 — This register should be written once finishing Reading from CR5A's mailbox written by proc 8 (access R/W1TC)
  [4n] R5SS0_CORE0_MBOX_READ_DONE_PROC_{n} (n=0..7) — This register should be written once finishing Reading from CR5A's mailbox written by proc {n} (access R/W1TC)
0x4010 MSS_CTRL_R5SS0_CORE0_SW_INT — This Register is used to generate a S/W Triggered Interrupt to R5SS0 Core0.
  [0] R5SS0_CORE0_SW_INT_PULSE — Write_pulse bit field:Writing 1'b1 to each bit will trigger MSS_SW_INT respectively to CR5A/B.
0x4020 MSS_CTRL_MPU_ADDR_ERRAGG_R5SS0_CORE0_MASK — This register Masks selected interrupt soures from generating MPU Address Error Interrupt to R5SS0 CORE0 .
  [24] MPU_ADDR_ERRAGG_R5SS0_CPU0_MASK_MPU_OSPI1_CFG_ADDR_ERR0 — Mask Error from MPU_ADDR_INTR to aggregated Error MPU_ADDR_INTR_ERRAGG1 : Error is Masked0 : Error is Unmasked
  [23] MPU_ADDR_ERRAGG_R5SS0_CPU0_MASK_MPU_OSPI1_ADDR_ERR0 — Mask Error from MPU_ADDR_INTR to aggregated Error MPU_ADDR_INTR_ERRAGG1 : Error is Masked0 : Error is Unmasked
  [19] MPU_ADDR_ERRAGG_R5SS0_CPU0_MASK_MPU_R5SS0_ADDR_ERR0 — Mask Error from MPU_ADDR_INTR to aggregated Error MPU_ADDR_INTR_ERRAGG1 : Error is Masked0 : Error is Unmasked
  [18] MPU_ADDR_ERRAGG_R5SS0_CPU0_MASK_MPU_OPTI_FLASH_ADDR_ERR0 — Mask Error from MPU_ADDR_INTR to aggregated Error MPU_ADDR_INTR_ERRAGG1 : Error is Masked0 : Error is Unmasked
  [17] MPU_ADDR_ERRAGG_R5SS0_CPU0_MASK_MPU_HSM_ADDR_ERR0 — Mask Error from MPU_ADDR_INTR to aggregated Error MPU_ADDR_INTR_ERRAGG1 : Error is Masked0 : Error is Unmasked
  [14] MPU_ADDR_ERRAGG_R5SS0_CPU0_MASK_MPU_CR5B0_AHB_ADDR_ERR0 — Mask Error from MPU_ADDR_INTR to aggregated Error MPU_ADDR_INTR_ERRAGG1 : Error is Masked0 : Error is Unmasked
  [13] MPU_ADDR_ERRAGG_R5SS0_CPU0_MASK_MPU_CR5A0_AHB_ADDR_ERR0 — Mask Error from MPU_ADDR_INTR to aggregated Error MPU_ADDR_INTR_ERRAGG1 : Error is Masked0 : Error is Unmasked
  [12] MPU_ADDR_ERRAGG_R5SS0_CPU0_MASK_MPU_SCRM2SCRP1_ADDR_ERR0 — Mask Error from MPU_ADDR_INTR to aggregated Error MPU_ADDR_INTR_ERRAGG1 : Error is Masked0 : Error is Unmasked
  [11] MPU_ADDR_ERRAGG_R5SS0_CPU0_MASK_MPU_SCRM2SCRP0_ADDR_ERR0 — Mask Error from MPU_ADDR_INTR to aggregated Error MPU_ADDR_INTR_ERRAGG1 : Error is Masked0 : Error is Unmasked
  [10] MPU_ADDR_ERRAGG_R5SS0_CPU0_MASK_MPU_OSPI_ADDR_ERR0 — Mask Error from MPU_ADDR_INTR to aggregated Error MPU_ADDR_INTR_ERRAGG1 : Error is Masked0 : Error is Unmasked
  [9] MPU_ADDR_ERRAGG_R5SS0_CPU0_MASK_MPU_MBOX_ADDR_ERR0 — Mask Error from MPU_ADDR_INTR to aggregated Error MPU_ADDR_INTR_ERRAGG1 : Error is Masked0 : Error is Unmasked
  [8] MPU_ADDR_ERRAGG_R5SS0_CPU0_MASK_MPU_DTHE_A_ADDR_ERR0 — Mask Error from MPU_ADDR_INTR to aggregated Error MPU_ADDR_INTR_ERRAGG1 : Error is Masked0 : Error is Unmasked
  [5] MPU_ADDR_ERRAGG_R5SS0_CPU0_MASK_MPU_CR5B0_AXIS_ADDR_ERR0 — Mask Error from MPU_ADDR_INTR to aggregated Error MPU_ADDR_INTR_ERRAGG1 : Error is Masked0 : Error is Unmasked
  [4] MPU_ADDR_ERRAGG_R5SS0_CPU0_MASK_MPU_CR5A0_AXIS_ADDR_ERR0 — Mask Error from MPU_ADDR_INTR to aggregated Error MPU_ADDR_INTR_ERRAGG1 : Error is Masked0 : Error is Unmasked
  [2] MPU_ADDR_ERRAGG_R5SS0_CPU0_MASK_MPU_L2_BANK_C_ADDR_ERR0 — Mask Error from MPU_ADDR_INTR to aggregated Error MPU_ADDR_INTR_ERRAGG1 : Error is Masked0 : Error is Unmasked
  [1] MPU_ADDR_ERRAGG_R5SS0_CPU0_MASK_MPU_L2_BANK_B_ADDR_ERR0 — Mask Error from MPU_ADDR_INTR to aggregated Error MPU_ADDR_INTR_ERRAGG1 : Error is Masked0 : Error is Unmasked
  [0] MPU_ADDR_ERRAGG_R5SS0_CPU0_MASK_MPU_L2_BANK_A_ADDR_ERR0 — Mask Error from MPU_ADDR_INTR to aggregated Error MPU_ADDR_INTR_ERRAGG1 : Error is Masked0 : Error is Unmasked
0x4024 MSS_CTRL_MPU_ADDR_ERRAGG_R5SS0_CORE0_STATUS access not given — This register shows the Status of Unmasked MPU Address Errors to R5SS0 Core0 .
  [24] MPU_ADDR_ERRAGG_R5SS0_CPU0_STATUS_MPU_OSPI1_CFG_ADDR_ERR0 — Status of Error from MPU_ADDR_INTR. Set only if Interupt is unmasked in MPU_ADDR_INTR_ERRAGG_MASKWrie 0x1 to clear this Error. (access R/W1TC)
  [23] MPU_ADDR_ERRAGG_R5SS0_CPU0_STATUS_MPU_OSPI1_ADDR_ERR0 — Status of Error from MPU_ADDR_INTR. Set only if Interupt is unmasked in MPU_ADDR_INTR_ERRAGG_MASKWrie 0x1 to clear this Error. (access R/W1TC)
  [19] MPU_ADDR_ERRAGG_R5SS0_CPU0_STATUS_MPU_R5SS0_ADDR_ERR0 — Status of Error from MPU_ADDR_INTR. Set only if Interupt is unmasked in MPU_ADDR_INTR_ERRAGG_MASKWrie 0x1 to clear this Error. (access R/W1TC)
  [18] MPU_ADDR_ERRAGG_R5SS0_CPU0_STATUS_MPU_OPTI_FLASH_ADDR_ERR0 — Status of Error from MPU_ADDR_INTR. Set only if Interupt is unmasked in MPU_ADDR_INTR_ERRAGG_MASKWrie 0x1 to clear this Error. (access R/W1TC)
  [17] MPU_ADDR_ERRAGG_R5SS0_CPU0_STATUS_MPU_HSM_ADDR_ERR0 — Status of Error from MPU_ADDR_INTR. Set only if Interupt is unmasked in MPU_ADDR_INTR_ERRAGG_MASKWrie 0x1 to clear this Error. (access R/W1TC)
  [14] MPU_ADDR_ERRAGG_R5SS0_CPU0_STATUS_MPU_CR5B0_AHB_ADDR_ERR0 — Status of Error from MPU_ADDR_INTR. Set only if Interupt is unmasked in MPU_ADDR_INTR_ERRAGG_MASKWrie 0x1 to clear this Error. (access R/W1TC)
  [13] MPU_ADDR_ERRAGG_R5SS0_CPU0_STATUS_MPU_CR5A0_AHB_ADDR_ERR0 — Status of Error from MPU_ADDR_INTR. Set only if Interupt is unmasked in MPU_ADDR_INTR_ERRAGG_MASKWrie 0x1 to clear this Error. (access R/W1TC)
  [12] MPU_ADDR_ERRAGG_R5SS0_CPU0_STATUS_MPU_SCRM2SCRP1_ADDR_ERR0 — Status of Error from MPU_ADDR_INTR. Set only if Interupt is unmasked in MPU_ADDR_INTR_ERRAGG_MASKWrie 0x1 to clear this Error. (access R/W1TC)
  [11] MPU_ADDR_ERRAGG_R5SS0_CPU0_STATUS_MPU_SCRM2SCRP0_ADDR_ERR0 — Status of Error from MPU_ADDR_INTR. Set only if Interupt is unmasked in MPU_ADDR_INTR_ERRAGG_MASKWrie 0x1 to clear this Error. (access R/W1TC)
  [10] MPU_ADDR_ERRAGG_R5SS0_CPU0_STATUS_MPU_OSPI_ADDR_ERR0 — Status of Error from MPU_ADDR_INTR. Set only if Interupt is unmasked in MPU_ADDR_INTR_ERRAGG_MASKWrie 0x1 to clear this Error. (access R/W1TC)
  [9] MPU_ADDR_ERRAGG_R5SS0_CPU0_STATUS_MPU_MBOX_ADDR_ERR0 — Status of Error from MPU_ADDR_INTR. Set only if Interupt is unmasked in MPU_ADDR_INTR_ERRAGG_MASKWrie 0x1 to clear this Error. (access R/W1TC)
  [8] MPU_ADDR_ERRAGG_R5SS0_CPU0_STATUS_MPU_DTHE_A_ADDR_ERR0 — Status of Error from MPU_ADDR_INTR. Set only if Interupt is unmasked in MPU_ADDR_INTR_ERRAGG_MASKWrie 0x1 to clear this Error. (access R/W1TC)
  [5] MPU_ADDR_ERRAGG_R5SS0_CPU0_STATUS_MPU_CR5B0_AXIS_ADDR_ERR0 — Status of Error from MPU_ADDR_INTR. Set only if Interupt is unmasked in MPU_ADDR_INTR_ERRAGG_MASKWrie 0x1 to clear this Error. (access R/W1TC)
  [4] MPU_ADDR_ERRAGG_R5SS0_CPU0_STATUS_MPU_CR5A0_AXIS_ADDR_ERR0 — Status of Error from MPU_ADDR_INTR. Set only if Interupt is unmasked in MPU_ADDR_INTR_ERRAGG_MASKWrie 0x1 to clear this Error. (access R/W1TC)
  [2] MPU_ADDR_ERRAGG_R5SS0_CPU0_STATUS_MPU_L2_BANK_C_ADDR_ERR0 — Status of Error from MPU_ADDR_INTR. Set only if Interupt is unmasked in MPU_ADDR_INTR_ERRAGG_MASKWrie 0x1 to clear this Error. (access R/W1TC)
  [1] MPU_ADDR_ERRAGG_R5SS0_CPU0_STATUS_MPU_L2_BANK_B_ADDR_ERR0 — Status of Error from MPU_ADDR_INTR. Set only if Interupt is unmasked in MPU_ADDR_INTR_ERRAGG_MASKWrie 0x1 to clear this Error. (access R/W1TC)
  [0] MPU_ADDR_ERRAGG_R5SS0_CPU0_STATUS_MPU_L2_BANK_A_ADDR_ERR0 — Status of Error from MPU_ADDR_INTR. Set only if Interupt is unmasked in MPU_ADDR_INTR_ERRAGG_MASKWrie 0x1 to clear this Error. (access R/W1TC)
